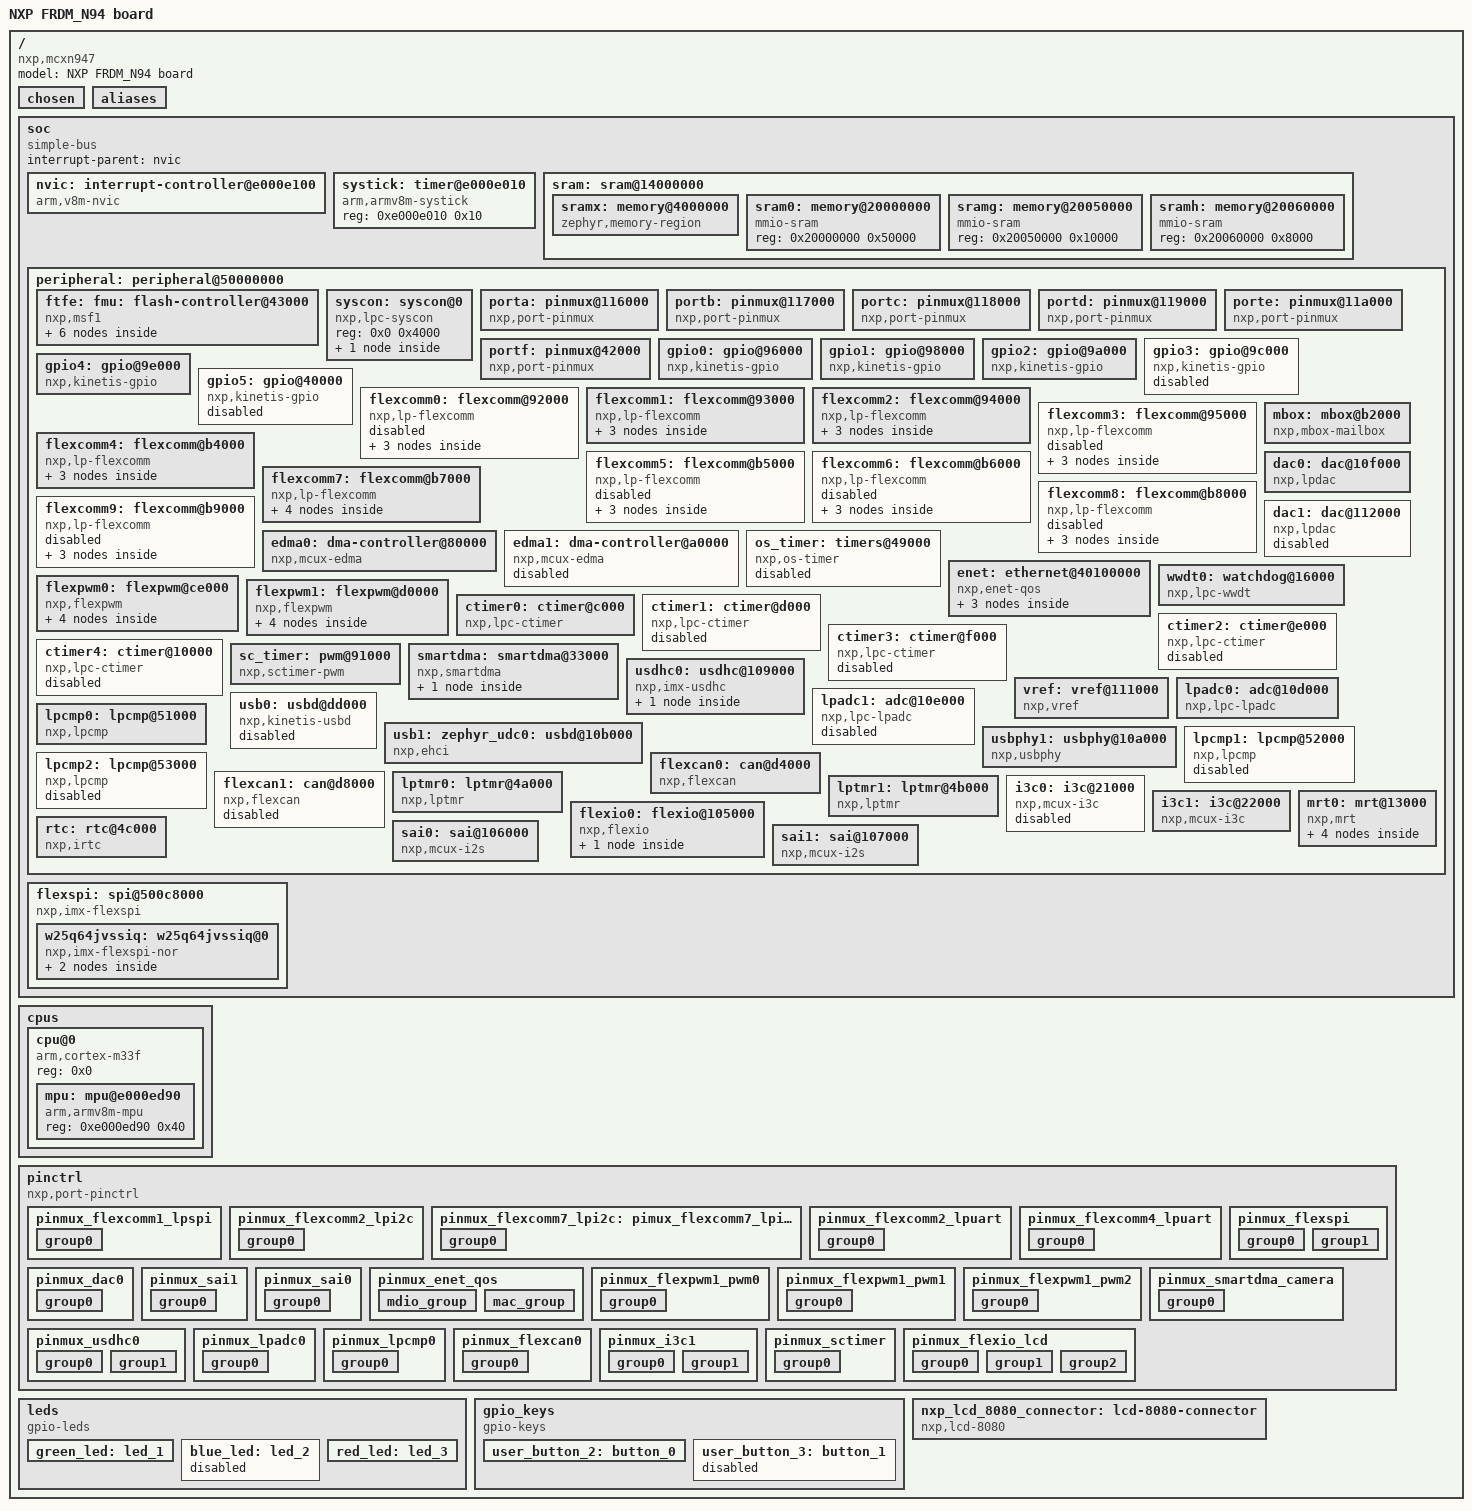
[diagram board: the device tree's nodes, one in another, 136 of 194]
/dts-v1/;

/ {
	#address-cells = < 0x1 >;
	#size-cells = < 0x1 >;
	model = "NXP FRDM_N94 board";
	compatible = "nxp,mcxn947", "nxp,mcx";
	chosen {
		zephyr,sram = &sram0;
		zephyr,flash = &flash;
		zephyr,flash-controller = &fmu;
		zephyr,code-partition = &slot0_partition;
		zephyr,uart-mcumgr = &flexcomm4_lpuart4;
		zephyr,console = &flexcomm4_lpuart4;
		zephyr,shell-uart = &flexcomm4_lpuart4;
		zephyr,canbus = &flexcan0;
		zephyr,code-cpu1-partition = &slot1_partition;
	};
	aliases {
		led0 = &red_led;
		led1 = &green_led;
		led2 = &blue_led;
		sw0 = &user_button_2;
		sw1 = &user_button_3;
		sdhc0 = &usdhc0;
		mcuboot-button0 = &user_button_2;
		watchdog0 = &wwdt0;
		pwm-0 = &flexpwm1_pwm0;
		pwm-1 = &sc_timer;
		rtc = &rtc;
	};
	soc {
		#address-cells = < 0x1 >;
		#size-cells = < 0x1 >;
		compatible = "simple-bus";
		interrupt-parent = < &nvic >;
		ranges;
		nvic: interrupt-controller@e000e100 {
			#address-cells = < 0x1 >;
			compatible = "arm,v8m-nvic";
			reg = < 0xe000e100 0xc00 >;
			interrupt-controller;
			#interrupt-cells = < 0x2 >;
			arm,num-irq-priority-bits = < 0x3 >;
			phandle = < 0x1 >;
		};
		systick: timer@e000e010 {
			compatible = "arm,armv8m-systick";
			reg = < 0xe000e010 0x10 >;
			status = "okay";
		};
		sram: sram@14000000 {
			ranges = < 0x4000000 0x14000000 0x20000000 >;
			#address-cells = < 0x1 >;
			#size-cells = < 0x1 >;
			sramx: memory@4000000 {
				compatible = "zephyr,memory-region", "mmio-sram";
				reg = < 0x4000000 0x18000 >;
				zephyr,memory-region = "SRAM1";
				zephyr,memory-attr = < 0x100000 >;
			};
			sram0: memory@20000000 {
				compatible = "mmio-sram";
				reg = < 0x20000000 0x50000 >;
			};
			sramg: memory@20050000 {
				compatible = "mmio-sram";
				reg = < 0x20050000 0x10000 >;
			};
			sramh: memory@20060000 {
				compatible = "mmio-sram";
				reg = < 0x20060000 0x8000 >;
			};
		};
		peripheral: peripheral@50000000 {
			ranges = < 0x0 0x50000000 0x10000000 >;
			#address-cells = < 0x1 >;
			#size-cells = < 0x1 >;
			ftfe: fmu: flash-controller@43000 {
				ranges = < 0x0 0x10000000 0x4000000 >;
				compatible = "nxp,msf1";
				reg = < 0x43000 0x1000 >;
				interrupts = < 0x8a 0x0 >;
				status = "okay";
				#address-cells = < 0x1 >;
				#size-cells = < 0x1 >;
				flash: flash@0 {
					compatible = "soc-nv-flash";
					reg = < 0x0 0x200000 >;
					erase-block-size = < 0x2000 >;
					write-block-size = < 0x80 >;
					partitions {
						compatible = "fixed-partitions";
						#address-cells = < 0x1 >;
						#size-cells = < 0x1 >;
						boot_partition: partition@0 {
							label = "mcuboot";
							reg = < 0x0 0x14000 >;
						};
						slot0_partition: partition@14000 {
							label = "image-0";
							reg = < 0x14000 0xf6000 >;
						};
						slot1_partition: partition@10A000 {
							label = "image-1";
							reg = < 0x10a000 0xf6000 >;
						};
					};
				};
				uuid: uuid@1100000 {
					compatible = "nxp,lpc-uid";
					reg = < 0x1100000 0x10 >;
				};
			};
			syscon: syscon@0 {
				compatible = "nxp,lpc-syscon";
				reg = < 0x0 0x4000 >;
				#clock-cells = < 0x1 >;
				phandle = < 0x2 >;
				reset: reset {
					compatible = "nxp,lpc-syscon-reset";
					#reset-cells = < 0x1 >;
					phandle = < 0x22 >;
				};
			};
			porta: pinmux@116000 {
				compatible = "nxp,port-pinmux";
				reg = < 0x116000 0x1000 >;
				clocks = < &syscon 0xc00 >;
				phandle = < 0x3 >;
			};
			portb: pinmux@117000 {
				compatible = "nxp,port-pinmux";
				reg = < 0x117000 0x1000 >;
				clocks = < &syscon 0xc01 >;
				phandle = < 0x4 >;
			};
			portc: pinmux@118000 {
				compatible = "nxp,port-pinmux";
				reg = < 0x118000 0x1000 >;
				clocks = < &syscon 0xc02 >;
				phandle = < 0x5 >;
			};
			portd: pinmux@119000 {
				compatible = "nxp,port-pinmux";
				reg = < 0x119000 0x1000 >;
				clocks = < &syscon 0xc03 >;
				phandle = < 0x6 >;
			};
			porte: pinmux@11a000 {
				compatible = "nxp,port-pinmux";
				reg = < 0x11a000 0x1000 >;
				clocks = < &syscon 0xc04 >;
				phandle = < 0x7 >;
			};
			portf: pinmux@42000 {
				compatible = "nxp,port-pinmux";
				reg = < 0x42000 0x1000 >;
				clocks = < &syscon 0xc05 >;
				phandle = < 0x8 >;
			};
			gpio0: gpio@96000 {
				compatible = "nxp,kinetis-gpio";
				status = "okay";
				reg = < 0x96000 0x1000 >;
				interrupts = < 0x11 0x0 >, < 0x12 0x0 >;
				gpio-controller;
				#gpio-cells = < 0x2 >;
				nxp,kinetis-port = < &porta >;
				phandle = < 0x20 >;
			};
			gpio1: gpio@98000 {
				compatible = "nxp,kinetis-gpio";
				status = "okay";
				reg = < 0x98000 0x1000 >;
				interrupts = < 0x13 0x0 >, < 0x14 0x0 >;
				gpio-controller;
				#gpio-cells = < 0x2 >;
				nxp,kinetis-port = < &portb >;
				phandle = < 0xf >;
			};
			gpio2: gpio@9a000 {
				compatible = "nxp,kinetis-gpio";
				status = "okay";
				reg = < 0x9a000 0x1000 >;
				interrupts = < 0x15 0x0 >, < 0x16 0x0 >;
				gpio-controller;
				#gpio-cells = < 0x2 >;
				nxp,kinetis-port = < &portc >;
				phandle = < 0x18 >;
			};
			gpio3: gpio@9c000 {
				compatible = "nxp,kinetis-gpio";
				status = "disabled";
				reg = < 0x9c000 0x1000 >;
				interrupts = < 0x17 0x0 >, < 0x18 0x0 >;
				gpio-controller;
				#gpio-cells = < 0x2 >;
				nxp,kinetis-port = < &portd >;
			};
			gpio4: gpio@9e000 {
				compatible = "nxp,kinetis-gpio";
				status = "okay";
				reg = < 0x9e000 0x1000 >;
				interrupts = < 0x19 0x0 >, < 0x1a 0x0 >;
				gpio-controller;
				#gpio-cells = < 0x2 >;
				nxp,kinetis-port = < &porte >;
				phandle = < 0x1f >;
			};
			gpio5: gpio@40000 {
				compatible = "nxp,kinetis-gpio";
				status = "disabled";
				reg = < 0x40000 0x1000 >;
				interrupts = < 0x1b 0x0 >, < 0x1c 0x0 >;
				gpio-controller;
				#gpio-cells = < 0x2 >;
				nxp,kinetis-port = < &portf >;
			};
			flexcomm0: flexcomm@92000 {
				compatible = "nxp,lp-flexcomm";
				reg = < 0x92000 0x1000 >;
				interrupts = < 0x23 0x0 >;
				status = "disabled";
				ranges;
				#address-cells = < 0x1 >;
				#size-cells = < 0x1 >;
				flexcomm0_lpuart0: lpuart@92000 {
					compatible = "nxp,lpuart";
					reg = < 0x92000 0x1000 >;
					clocks = < &syscon 0x100 >;
					status = "disabled";
				};
				flexcomm0_lpspi0: spi@92000 {
					compatible = "nxp,lpspi";
					reg = < 0x92000 0x1000 >;
					clocks = < &syscon 0x100 >;
					#address-cells = < 0x1 >;
					#size-cells = < 0x0 >;
					tx-fifo-size = < 0x8 >;
					rx-fifo-size = < 0x8 >;
					status = "disabled";
				};
				flexcomm0_lpi2c0: lpi2c@92800 {
					compatible = "nxp,lpi2c";
					reg = < 0x92800 0x1000 >;
					clocks = < &syscon 0x100 >;
					#address-cells = < 0x1 >;
					#size-cells = < 0x0 >;
					status = "disabled";
				};
			};
			flexcomm1: flexcomm@93000 {
				compatible = "nxp,lp-flexcomm";
				reg = < 0x93000 0x1000 >;
				interrupts = < 0x24 0x0 >;
				status = "okay";
				ranges;
				#address-cells = < 0x1 >;
				#size-cells = < 0x1 >;
				flexcomm1_lpuart1: lpuart@93000 {
					compatible = "nxp,lpuart";
					reg = < 0x93000 0x1000 >;
					clocks = < &syscon 0x101 >;
					dmas = < &edma0 0x0 0x47 >, < &edma0 0x1 0x48 >;
					dma-names = "rx", "tx";
					status = "disabled";
				};
				flexcomm1_lpspi1: spi@93000 {
					compatible = "nxp,lpspi";
					reg = < 0x93000 0x1000 >;
					clocks = < &syscon 0x101 >;
					#address-cells = < 0x1 >;
					#size-cells = < 0x0 >;
					dmas = < &edma0 0x0 0x47 >, < &edma0 0x1 0x48 >;
					dma-names = "rx", "tx";
					tx-fifo-size = < 0x8 >;
					rx-fifo-size = < 0x8 >;
					status = "okay";
					pinctrl-0 = < &pinmux_flexcomm1_lpspi >;
					pinctrl-names = "default";
				};
				flexcomm1_lpi2c1: lpi2c@93800 {
					compatible = "nxp,lpi2c";
					reg = < 0x93800 0x1000 >;
					clocks = < &syscon 0x101 >;
					#address-cells = < 0x1 >;
					#size-cells = < 0x0 >;
					status = "disabled";
				};
			};
			flexcomm2: flexcomm@94000 {
				compatible = "nxp,lp-flexcomm";
				reg = < 0x94000 0x1000 >;
				interrupts = < 0x25 0x0 >;
				status = "okay";
				ranges;
				#address-cells = < 0x1 >;
				#size-cells = < 0x1 >;
				flexcomm2_lpuart2: lpuart@94000 {
					compatible = "nxp,lpuart";
					reg = < 0x94000 0x1000 >;
					clocks = < &syscon 0x102 >;
					dmas = < &edma0 0x4 0x49 >, < &edma0 0x5 0x4a >;
					dma-names = "rx", "tx";
					status = "okay";
					current-speed = < 0x1c200 >;
					pinctrl-0 = < &pinmux_flexcomm2_lpuart >;
					pinctrl-names = "default";
				};
				flexcomm2_lpspi2: spi@94000 {
					compatible = "nxp,lpspi";
					reg = < 0x94000 0x1000 >;
					clocks = < &syscon 0x102 >;
					#address-cells = < 0x1 >;
					#size-cells = < 0x0 >;
					dmas = < &edma0 0x4 0x49 >, < &edma0 0x5 0x4a >;
					dma-names = "rx", "tx";
					tx-fifo-size = < 0x8 >;
					rx-fifo-size = < 0x8 >;
					status = "disabled";
				};
				flexcomm2_lpi2c2: nxp_8080_touch_panel_i2c: lpi2c@94800 {
					compatible = "nxp,lpi2c";
					reg = < 0x94800 0x1000 >;
					clocks = < &syscon 0x102 >;
					#address-cells = < 0x1 >;
					#size-cells = < 0x0 >;
					status = "okay";
					pinctrl-0 = < &pinmux_flexcomm2_lpi2c >;
					pinctrl-names = "default";
					clock-frequency = < 0x186a0 >;
				};
			};
			flexcomm3: flexcomm@95000 {
				compatible = "nxp,lp-flexcomm";
				reg = < 0x95000 0x1000 >;
				interrupts = < 0x26 0x0 >;
				status = "disabled";
				ranges;
				#address-cells = < 0x1 >;
				#size-cells = < 0x1 >;
				flexcomm3_lpuart3: lpuart@95000 {
					compatible = "nxp,lpuart";
					reg = < 0x95000 0x1000 >;
					clocks = < &syscon 0x103 >;
					status = "disabled";
				};
				flexcomm3_lpspi3: spi@95000 {
					compatible = "nxp,lpspi";
					reg = < 0x95000 0x1000 >;
					clocks = < &syscon 0x103 >;
					#address-cells = < 0x1 >;
					#size-cells = < 0x0 >;
					tx-fifo-size = < 0x8 >;
					rx-fifo-size = < 0x8 >;
					status = "disabled";
				};
				flexcomm3_lpi2c3: lpi2c@95800 {
					compatible = "nxp,lpi2c";
					reg = < 0x95800 0x1000 >;
					clocks = < &syscon 0x103 >;
					#address-cells = < 0x1 >;
					#size-cells = < 0x0 >;
					status = "disabled";
				};
			};
			flexcomm4: flexcomm@b4000 {
				compatible = "nxp,lp-flexcomm";
				reg = < 0xb4000 0x1000 >;
				interrupts = < 0x27 0x0 >;
				status = "okay";
				ranges;
				#address-cells = < 0x1 >;
				#size-cells = < 0x1 >;
				flexcomm4_lpuart4: lpuart@b4000 {
					compatible = "nxp,lpuart";
					reg = < 0xb4000 0x1000 >;
					clocks = < &syscon 0x104 >;
					dmas = < &edma0 0x2 0x4d >, < &edma0 0x3 0x4e >;
					dma-names = "rx", "tx";
					status = "okay";
					current-speed = < 0x1c200 >;
					pinctrl-0 = < &pinmux_flexcomm4_lpuart >;
					pinctrl-names = "default";
				};
				flexcomm4_lpspi4: spi@b4000 {
					compatible = "nxp,lpspi";
					reg = < 0xb4000 0x1000 >;
					clocks = < &syscon 0x104 >;
					#address-cells = < 0x1 >;
					#size-cells = < 0x0 >;
					dmas = < &edma0 0x2 0x4d >, < &edma0 0x3 0x4e >;
					dma-names = "rx", "tx";
					tx-fifo-size = < 0x8 >;
					rx-fifo-size = < 0x8 >;
					status = "disabled";
				};
				flexcomm4_lpi2c4: lpi2c@b4800 {
					compatible = "nxp,lpi2c";
					reg = < 0xb4800 0x1000 >;
					clocks = < &syscon 0x104 >;
					#address-cells = < 0x1 >;
					#size-cells = < 0x0 >;
					status = "disabled";
				};
			};
			flexcomm5: flexcomm@b5000 {
				compatible = "nxp,lp-flexcomm";
				reg = < 0xb5000 0x1000 >;
				interrupts = < 0x28 0x0 >;
				status = "disabled";
				ranges;
				#address-cells = < 0x1 >;
				#size-cells = < 0x1 >;
				flexcomm5_lpuart5: lpuart@b5000 {
					compatible = "nxp,lpuart";
					reg = < 0xb5000 0x1000 >;
					clocks = < &syscon 0x105 >;
					status = "disabled";
				};
				flexcomm5_lpspi5: spi@b5000 {
					compatible = "nxp,lpspi";
					reg = < 0xb5000 0x1000 >;
					clocks = < &syscon 0x105 >;
					#address-cells = < 0x1 >;
					#size-cells = < 0x0 >;
					tx-fifo-size = < 0x8 >;
					rx-fifo-size = < 0x8 >;
					status = "disabled";
				};
				flexcomm5_lpi2c5: lpi2c@b5800 {
					compatible = "nxp,lpi2c";
					reg = < 0xb5800 0x1000 >;
					clocks = < &syscon 0x105 >;
					#address-cells = < 0x1 >;
					#size-cells = < 0x0 >;
					status = "disabled";
				};
			};
			flexcomm6: flexcomm@b6000 {
				compatible = "nxp,lp-flexcomm";
				reg = < 0xb6000 0x1000 >;
				interrupts = < 0x29 0x0 >;
				status = "disabled";
				ranges;
				#address-cells = < 0x1 >;
				#size-cells = < 0x1 >;
				flexcomm6_lpuart6: lpuart@b6000 {
					compatible = "nxp,lpuart";
					reg = < 0xb6000 0x1000 >;
					clocks = < &syscon 0x106 >;
					status = "disabled";
				};
				flexcomm6_lpspi6: spi@b6000 {
					compatible = "nxp,lpspi";
					reg = < 0xb6000 0x1000 >;
					clocks = < &syscon 0x106 >;
					#address-cells = < 0x1 >;
					#size-cells = < 0x0 >;
					tx-fifo-size = < 0x8 >;
					rx-fifo-size = < 0x8 >;
					status = "disabled";
				};
				flexcomm6_lpi2c6: lpi2c@b6800 {
					compatible = "nxp,lpi2c";
					reg = < 0xb6800 0x1000 >;
					clocks = < &syscon 0x106 >;
					#address-cells = < 0x1 >;
					#size-cells = < 0x0 >;
					status = "disabled";
				};
			};
			flexcomm7: flexcomm@b7000 {
				compatible = "nxp,lp-flexcomm";
				reg = < 0xb7000 0x1000 >;
				interrupts = < 0x2a 0x0 >;
				status = "okay";
				ranges;
				#address-cells = < 0x1 >;
				#size-cells = < 0x1 >;
				flexcomm7_lpuart7: lpuart@b7000 {
					compatible = "nxp,lpuart";
					reg = < 0xb7000 0x1000 >;
					clocks = < &syscon 0x107 >;
					status = "disabled";
				};
				flexcomm7_lpspi7: spi@b7000 {
					compatible = "nxp,lpspi";
					reg = < 0xb7000 0x1000 >;
					clocks = < &syscon 0x107 >;
					#address-cells = < 0x1 >;
					#size-cells = < 0x0 >;
					tx-fifo-size = < 0x8 >;
					rx-fifo-size = < 0x8 >;
					status = "disabled";
				};
				flexcomm7_lpi2c7: lpi2c@b7800 {
					compatible = "nxp,lpi2c";
					reg = < 0xb7800 0x1000 >;
					clocks = < &syscon 0x107 >;
					#address-cells = < 0x1 >;
					#size-cells = < 0x0 >;
					status = "okay";
					pinctrl-0 = < &pinmux_flexcomm7_lpi2c >;
					pinctrl-names = "default";
					clock-frequency = < 0x186a0 >;
					ov7670: ov7670@21 {
						compatible = "ovti,ov7670";
						reset-gpios = < &gpio1 0x13 0x0 >;
						pwdn-gpios = < &gpio1 0x12 0x0 >;
						reg = < 0x21 >;
						phandle = < 0x16 >;
					};
				};
			};
			flexcomm8: flexcomm@b8000 {
				compatible = "nxp,lp-flexcomm";
				reg = < 0xb8000 0x1000 >;
				interrupts = < 0x2b 0x0 >;
				status = "disabled";
				ranges;
				#address-cells = < 0x1 >;
				#size-cells = < 0x1 >;
				flexcomm8_lpuart8: lpuart@b8000 {
					compatible = "nxp,lpuart";
					reg = < 0xb8000 0x1000 >;
					clocks = < &syscon 0x108 >;
					status = "disabled";
				};
				flexcomm8_lpspi8: spi@b8000 {
					compatible = "nxp,lpspi";
					reg = < 0xb8000 0x1000 >;
					clocks = < &syscon 0x108 >;
					#address-cells = < 0x1 >;
					#size-cells = < 0x0 >;
					tx-fifo-size = < 0x8 >;
					rx-fifo-size = < 0x8 >;
					status = "disabled";
				};
				flexcomm8_lpi2c8: lpi2c@b8800 {
					compatible = "nxp,lpi2c";
					reg = < 0xb8800 0x1000 >;
					clocks = < &syscon 0x108 >;
					#address-cells = < 0x1 >;
					#size-cells = < 0x0 >;
					status = "disabled";
				};
			};
			flexcomm9: flexcomm@b9000 {
				compatible = "nxp,lp-flexcomm";
				reg = < 0xb9000 0x1000 >;
				interrupts = < 0x2c 0x0 >;
				status = "disabled";
				ranges;
				#address-cells = < 0x1 >;
				#size-cells = < 0x1 >;
				flexcomm9_lpuart9: lpuart@b9000 {
					compatible = "nxp,lpuart";
					reg = < 0xb9000 0x1000 >;
					clocks = < &syscon 0x109 >;
					status = "disabled";
				};
				flexcomm9_lpspi9: spi@b9000 {
					compatible = "nxp,lpspi";
					reg = < 0xb9000 0x1000 >;
					clocks = < &syscon 0x109 >;
					#address-cells = < 0x1 >;
					#size-cells = < 0x0 >;
					tx-fifo-size = < 0x8 >;
					rx-fifo-size = < 0x8 >;
					status = "disabled";
				};
				flexcomm9_lpi2c9: lpi2c@b9800 {
					compatible = "nxp,lpi2c";
					reg = < 0xb9800 0x1000 >;
					clocks = < &syscon 0x109 >;
					#address-cells = < 0x1 >;
					#size-cells = < 0x0 >;
					status = "disabled";
				};
			};
			mbox: mbox@b2000 {
				compatible = "nxp,mbox-mailbox";
				reg = < 0xb2000 0xec >;
				interrupts = < 0x36 0x0 >;
				rx-channels = < 0x4 >;
				#mbox-cells = < 0x1 >;
				status = "okay";
			};
			edma0: dma-controller@80000 {
				#dma-cells = < 0x2 >;
				compatible = "nxp,mcux-edma";
				nxp,version = < 0x4 >;
				dma-channels = < 0x10 >;
				dma-requests = < 0x78 >;
				reg = < 0x80000 0x1000 >;
				interrupts = < 0x1 0x0 >, < 0x2 0x0 >, < 0x3 0x0 >, < 0x4 0x0 >, < 0x5 0x0 >, < 0x6 0x0 >, < 0x7 0x0 >, < 0x8 0x0 >, < 0x9 0x0 >, < 0xa 0x0 >, < 0xb 0x0 >, < 0xc 0x0 >, < 0xd 0x0 >, < 0xe 0x0 >, < 0xf 0x0 >, < 0x10 0x0 >;
				no-error-irq;
				status = "okay";
				phandle = < 0x9 >;
			};
			edma1: dma-controller@a0000 {
				#dma-cells = < 0x2 >;
				compatible = "nxp,mcux-edma";
				nxp,version = < 0x4 >;
				dma-channels = < 0x10 >;
				dma-requests = < 0x78 >;
				reg = < 0xa0000 0x1000 >;
				interrupts = < 0x4d 0x0 >, < 0x4e 0x0 >, < 0x4f 0x0 >, < 0x50 0x0 >, < 0x51 0x0 >, < 0x52 0x0 >, < 0x53 0x0 >, < 0x54 0x0 >, < 0x55 0x0 >, < 0x56 0x0 >, < 0x57 0x0 >, < 0x58 0x0 >, < 0x59 0x0 >, < 0x5a 0x0 >, < 0x5b 0x0 >, < 0x5c 0x0 >;
				no-error-irq;
				status = "disabled";
			};
			os_timer: timers@49000 {
				compatible = "nxp,os-timer";
				reg = < 0x49000 0x1000 >;
				interrupts = < 0x39 0x0 >;
				status = "disabled";
			};
			dac0: dac@10f000 {
				compatible = "nxp,lpdac";
				reg = < 0x10f000 0x1000 >;
				interrupts = < 0x6a 0x0 >;
				status = "okay";
				voltage-reference = < 0x0 >;
				#io-channel-cells = < 0x1 >;
				pinctrl-0 = < &pinmux_dac0 >;
				pinctrl-names = "default";
			};
			dac1: dac@112000 {
				compatible = "nxp,lpdac";
				reg = < 0x112000 0x1000 >;
				interrupts = < 0x6b 0x0 >;
				status = "disabled";
				voltage-reference = < 0x0 >;
				#io-channel-cells = < 0x1 >;
			};
			enet: ethernet@40100000 {
				compatible = "nxp,enet-qos";
				reg = < 0x40100000 0x1200 >;
				clocks = < &syscon 0xd00 >;
				pinctrl-0 = < &pinmux_enet_qos >;
				pinctrl-names = "default";
				status = "okay";
				enet_mac: ethernet {
					compatible = "nxp,enet-qos-mac";
					status = "okay";
					interrupts = < 0x8b 0x0 >, < 0x8c 0x0 >, < 0x8d 0x0 >;
					interrupt-names = "mac", "power", "lpi";
					phy-connection-type = "rmii";
					zephyr,random-mac-address;
					phy-handle = < &phy >;
				};
				enet_mdio: mdio {
					#address-cells = < 0x1 >;
					#size-cells = < 0x0 >;
					compatible = "nxp,enet-qos-mdio";
					status = "okay";
					phy: ethernet-phy@0 {
						compatible = "ethernet-phy";
						reg = < 0x0 >;
						status = "okay";
						phandle = < 0x12 >;
					};
				};
			};
			wwdt0: watchdog@16000 {
				compatible = "nxp,lpc-wwdt";
				reg = < 0x16000 0x1000 >;
				interrupts = < 0x98 0x0 >;
				status = "okay";
				clk-divider = < 0x1 >;
			};
			flexpwm0: flexpwm@ce000 {
				compatible = "nxp,flexpwm";
				reg = < 0xce000 0x1000 >;
				interrupt-names = "RELOAD-ERROR", "FAULT";
				interrupts = < 0x70 0x0 >, < 0x71 0x0 >;
				flexpwm0_pwm0: pwm0 {
					compatible = "nxp,imx-pwm";
					index = < 0x0 >;
					interrupts = < 0x72 0x0 >;
					#pwm-cells = < 0x3 >;
					clocks = < &syscon 0x400 >;
					nxp,prescaler = < 0x80 >;
					status = "disabled";
					run-in-wait;
				};
				flexpwm0_pwm1: pwm1 {
					compatible = "nxp,imx-pwm";
					index = < 0x1 >;
					interrupts = < 0x73 0x0 >;
					#pwm-cells = < 0x3 >;
					clocks = < &syscon 0x400 >;
					nxp,prescaler = < 0x80 >;
					status = "disabled";
					run-in-wait;
				};
				flexpwm0_pwm2: pwm2 {
					compatible = "nxp,imx-pwm";
					index = < 0x2 >;
					interrupts = < 0x74 0x0 >;
					#pwm-cells = < 0x3 >;
					clocks = < &syscon 0x400 >;
					nxp,prescaler = < 0x80 >;
					status = "disabled";
					run-in-wait;
				};
				flexpwm0_pwm3: pwm3 {
					compatible = "nxp,imx-pwm";
					index = < 0x3 >;
					interrupts = < 0x75 0x0 >;
					#pwm-cells = < 0x3 >;
					clocks = < &syscon 0x400 >;
					nxp,prescaler = < 0x80 >;
					status = "disabled";
					run-in-wait;
				};
			};
			flexpwm1: flexpwm@d0000 {
				compatible = "nxp,flexpwm";
				reg = < 0xd0000 0x1000 >;
				interrupt-names = "RELOAD-ERROR", "FAULT";
				interrupts = < 0x76 0x0 >, < 0x77 0x0 >;
				flexpwm1_pwm0: pwm0 {
					compatible = "nxp,imx-pwm";
					index = < 0x0 >;
					interrupts = < 0x78 0x0 >;
					#pwm-cells = < 0x3 >;
					clocks = < &syscon 0x400 >;
					nxp,prescaler = < 0x80 >;
					status = "okay";
					run-in-wait;
					pinctrl-0 = < &pinmux_flexpwm1_pwm0 >;
					pinctrl-names = "default";
				};
				flexpwm1_pwm1: pwm1 {
					compatible = "nxp,imx-pwm";
					index = < 0x1 >;
					interrupts = < 0x79 0x0 >;
					#pwm-cells = < 0x3 >;
					clocks = < &syscon 0x400 >;
					nxp,prescaler = < 0x80 >;
					status = "disabled";
					run-in-wait;
				};
				flexpwm1_pwm2: pwm2 {
					compatible = "nxp,imx-pwm";
					index = < 0x2 >;
					interrupts = < 0x7a 0x0 >;
					#pwm-cells = < 0x3 >;
					clocks = < &syscon 0x400 >;
					nxp,prescaler = < 0x80 >;
					status = "disabled";
					run-in-wait;
				};
				flexpwm1_pwm3: pwm3 {
					compatible = "nxp,imx-pwm";
					index = < 0x3 >;
					interrupts = < 0x7b 0x0 >;
					#pwm-cells = < 0x3 >;
					clocks = < &syscon 0x400 >;
					nxp,prescaler = < 0x80 >;
					status = "disabled";
					run-in-wait;
				};
			};
			ctimer0: ctimer@c000 {
				compatible = "nxp,lpc-ctimer";
				reg = < 0xc000 0x1000 >;
				interrupts = < 0x1f 0x0 >;
				status = "okay";
				clk-source = < 0x1 >;
				clocks = < &syscon 0x0 >;
				mode = < 0x0 >;
				input = < 0x0 >;
				prescale = < 0x0 >;
			};
			ctimer1: ctimer@d000 {
				compatible = "nxp,lpc-ctimer";
				reg = < 0xd000 0x1000 >;
				interrupts = < 0x20 0x0 >;
				status = "disabled";
				clk-source = < 0x1 >;
				clocks = < &syscon 0x1 >;
				mode = < 0x0 >;
				input = < 0x0 >;
				prescale = < 0x0 >;
			};
			ctimer2: ctimer@e000 {
				compatible = "nxp,lpc-ctimer";
				reg = < 0xe000 0x1000 >;
				interrupts = < 0x22 0x0 >;
				status = "disabled";
				clk-source = < 0x1 >;
				clocks = < &syscon 0x2 >;
				mode = < 0x0 >;
				input = < 0x0 >;
				prescale = < 0x0 >;
			};
			ctimer3: ctimer@f000 {
				compatible = "nxp,lpc-ctimer";
				reg = < 0xf000 0x1000 >;
				interrupts = < 0x37 0x0 >;
				status = "disabled";
				clk-source = < 0x1 >;
				clocks = < &syscon 0x3 >;
				mode = < 0x0 >;
				input = < 0x0 >;
				prescale = < 0x0 >;
			};
			ctimer4: ctimer@10000 {
				compatible = "nxp,lpc-ctimer";
				reg = < 0x10000 0x1000 >;
				interrupts = < 0x38 0x0 >;
				status = "disabled";
				clk-source = < 0x1 >;
				clocks = < &syscon 0x4 >;
				mode = < 0x0 >;
				input = < 0x0 >;
				prescale = < 0x0 >;
			};
			sc_timer: pwm@91000 {
				compatible = "nxp,sctimer-pwm";
				reg = < 0x91000 0x1000 >;
				interrupts = < 0x21 0x0 >;
				clocks = < &syscon 0x900 >;
				status = "okay";
				prescaler = < 0x1 >;
				#pwm-cells = < 0x3 >;
				pinctrl-0 = < &pinmux_sctimer >;
				pinctrl-names = "default";
			};
			smartdma: smartdma@33000 {
				compatible = "nxp,smartdma";
				reg = < 0x33000 0x1000 >;
				status = "okay";
				interrupts = < 0x35 0x0 >;
				program-mem = < 0x4000000 >;
				#dma-cells = < 0x0 >;
				video_sdma: video-sdma {
					status = "okay";
					compatible = "nxp,video-smartdma";
					pinctrl-0 = < &pinmux_smartdma_camera >;
					pinctrl-names = "default";
					sensor = < &ov7670 >;
					vsync-pin = < 0x4 >;
					hsync-pin = < 0xb >;
					pclk-pin = < 0x5 >;
				};
			};
			usdhc0: usdhc@109000 {
				compatible = "nxp,imx-usdhc";
				reg = < 0x109000 0x1000 >;
				interrupts = < 0x3d 0x0 >;
				status = "okay";
				clocks = < &syscon 0x200 >;
				max-bus-freq = < 0x3197500 >;
				min-bus-freq = < 0x61a80 >;
				pinctrl-0 = < &pinmux_usdhc0 >;
				pinctrl-1 = < &pinmux_usdhc0 >;
				pinctrl-2 = < &pinmux_usdhc0 >;
				cd-gpios = < &gpio2 0x1 0x1 >;
				pinctrl-names = "default", "slow", "med";
				no-1-8-v;
				sdmmc {
					compatible = "zephyr,sdmmc-disk";
					disk-name = "SD";
					status = "okay";
				};
			};
			vref: vref@111000 {
				compatible = "nxp,vref";
				regulator-name = "mcxn94x-vref";
				reg = < 0x111000 0x14 >;
				status = "okay";
				#nxp,reference-cells = < 0x1 >;
				nxp,buffer-startup-delay-us = < 0x190 >;
				nxp,bandgap-startup-time-us = < 0x14 >;
				regulator-min-microvolt = < 0xf4240 >;
				regulator-max-microvolt = < 0x200b20 >;
				phandle = < 0x19 >;
			};
			lpadc0: adc@10d000 {
				compatible = "nxp,lpc-lpadc";
				reg = < 0x10d000 0x1000 >;
				interrupts = < 0x2d 0x0 >;
				status = "okay";
				voltage-ref = < 0x1 >;
				calibration-average = < 0x80 >;
				power-level = < 0x0 >;
				offset-value-a = < 0x0 >;
				offset-value-b = < 0x0 >;
				#io-channel-cells = < 0x1 >;
				clocks = < &syscon 0xf00 >;
				nxp,references = < &vref 0x708 >;
				pinctrl-0 = < &pinmux_lpadc0 >;
				pinctrl-names = "default";
			};
			lpadc1: adc@10e000 {
				compatible = "nxp,lpc-lpadc";
				reg = < 0x10e000 0x1000 >;
				interrupts = < 0x2e 0x0 >;
				status = "disabled";
				voltage-ref = < 0x0 >;
				calibration-average = < 0x80 >;
				power-level = < 0x1 >;
				offset-value-a = < 0x0 >;
				offset-value-b = < 0x0 >;
				#io-channel-cells = < 0x1 >;
				clocks = < &syscon 0xf01 >;
			};
			usb0: usbd@dd000 {
				compatible = "nxp,kinetis-usbd";
				reg = < 0xdd000 0x1000 >;
				interrupts = < 0x32 0x1 >;
				interrupt-names = "usbfs0";
				num-bidir-endpoints = < 0x10 >;
				no-voltage-regulator;
				status = "disabled";
			};
			usb1: zephyr_udc0: usbd@10b000 {
				compatible = "nxp,ehci";
				reg = < 0x10b000 0x1000 >;
				interrupts = < 0x43 0x0 >;
				interrupt-names = "usb_otg";
				num-bidir-endpoints = < 0x8 >;
				status = "okay";
				phy-handle = < &usbphy1 >;
			};
			usbphy1: usbphy@10a000 {
				compatible = "nxp,usbphy";
				reg = < 0x10a000 0x1000 >;
				status = "okay";
				tx-d-cal = < 0x4 >;
				tx-cal-45-dp-ohms = < 0x7 >;
				tx-cal-45-dm-ohms = < 0x7 >;
				phandle = < 0x1b >;
			};
			lpcmp0: lpcmp@51000 {
				compatible = "nxp,lpcmp";
				reg = < 0x51000 0x1000 >;
				interrupts = < 0x6d 0x0 >;
				status = "okay";
				#io-channel-cells = < 0x2 >;
				pinctrl-0 = < &pinmux_lpcmp0 >;
				pinctrl-names = "default";
			};
			lpcmp1: lpcmp@52000 {
				compatible = "nxp,lpcmp";
				reg = < 0x52000 0x1000 >;
				interrupts = < 0x6e 0x0 >;
				status = "disabled";
				#io-channel-cells = < 0x2 >;
			};
			lpcmp2: lpcmp@53000 {
				compatible = "nxp,lpcmp";
				reg = < 0x53000 0x1000 >;
				interrupts = < 0x6f 0x0 >;
				status = "disabled";
				#io-channel-cells = < 0x2 >;
			};
			flexcan0: can@d4000 {
				compatible = "nxp,flexcan";
				reg = < 0xd4000 0x4000 >;
				interrupts = < 0x3e 0x0 >;
				interrupt-names = "common";
				clocks = < &syscon 0x1000 >;
				clk-source = < 0x0 >;
				status = "okay";
				pinctrl-0 = < &pinmux_flexcan0 >;
				pinctrl-names = "default";
			};
			flexcan1: can@d8000 {
				compatible = "nxp,flexcan";
				reg = < 0xd8000 0x4000 >;
				interrupts = < 0x3f 0x0 >;
				interrupt-names = "common";
				clocks = < &syscon 0x1001 >;
				clk-source = < 0x0 >;
				status = "disabled";
			};
			lptmr0: lptmr@4a000 {
				compatible = "nxp,lptmr";
				reg = < 0x4a000 0x1000 >;
				interrupts = < 0x8f 0x0 >;
				clock-frequency = < 0x3e80 >;
				prescaler = < 0x1 >;
				clk-source = < 0x1 >;
				resolution = < 0x20 >;
				status = "okay";
			};
			lptmr1: lptmr@4b000 {
				compatible = "nxp,lptmr";
				reg = < 0x4b000 0x1000 >;
				interrupts = < 0x90 0x0 >;
				clock-frequency = < 0x3e80 >;
				prescaler = < 0x1 >;
				clk-source = < 0x1 >;
				resolution = < 0x20 >;
			};
			i3c0: i3c@21000 {
				compatible = "nxp,mcux-i3c";
				reg = < 0x21000 0x1000 >;
				interrupts = < 0x5f 0x0 >;
				clocks = < &syscon 0x600 >;
				clk-divider = < 0x6 >;
				clk-divider-slow = < 0x1 >;
				clk-divider-tc = < 0x1 >;
				status = "disabled";
				#address-cells = < 0x3 >;
				#size-cells = < 0x0 >;
			};
			i3c1: i3c@22000 {
				compatible = "nxp,mcux-i3c";
				reg = < 0x22000 0x1000 >;
				interrupts = < 0x60 0x0 >;
				clocks = < &syscon 0x601 >;
				clk-divider = < 0x6 >;
				clk-divider-slow = < 0x1 >;
				clk-divider-tc = < 0x1 >;
				status = "okay";
				#address-cells = < 0x3 >;
				#size-cells = < 0x0 >;
				pinctrl-0 = < &pinmux_i3c1 >;
				pinctrl-names = "default";
			};
			flexio0: flexio@105000 {
				compatible = "nxp,flexio";
				reg = < 0x105000 0x1000 >;
				status = "okay";
				interrupts = < 0x69 0x0 >;
				clocks = < &syscon 0x1100 >;
				flexio0_lcd: zephyr_mipi_dbi_parallel: flexio0-lcd {
					compatible = "nxp,mipi-dbi-flexio-lcdif";
					status = "disabled";
					dmas = < &edma0 0x0 0x3d >;
					dma-names = "tx";
					shifters-count = < 0x8 >;
					timers-count = < 0x1 >;
					enwr-pin = < 0x1 >;
					rd-pin = < 0x0 >;
					data-pin-start = < 0x10 >;
					reset-gpios = < &gpio4 0x7 0x0 >;
					cs-gpios = < &gpio0 0xc 0x0 >;
					rs-gpios = < &gpio0 0x7 0x0 >;
					pinctrl-0 = < &pinmux_flexio_lcd >;
					pinctrl-names = "default";
				};
			};
			mrt0: mrt@13000 {
				compatible = "nxp,mrt";
				reg = < 0x13000 0x1000 >;
				interrupts = < 0x1e 0x0 >;
				num-channels = < 0x4 >;
				num-bits = < 0x18 >;
				clocks = < &syscon 0xb00 >;
				resets = < &reset 0x10000 >;
				#address-cells = < 0x1 >;
				#size-cells = < 0x0 >;
				mrt0_channel0: mrt0_channel@0 {
					compatible = "nxp,mrt-channel";
					reg = < 0x0 >;
					status = "okay";
				};
				mrt0_channel1: mrt0_channel@1 {
					compatible = "nxp,mrt-channel";
					reg = < 0x1 >;
					status = "disabled";
				};
				mrt0_channel2: mrt0_channel@2 {
					compatible = "nxp,mrt-channel";
					reg = < 0x2 >;
					status = "disabled";
				};
				mrt0_channel3: mrt0_channel@3 {
					compatible = "nxp,mrt-channel";
					reg = < 0x3 >;
					status = "disabled";
				};
			};
			rtc: rtc@4c000 {
				compatible = "nxp,irtc";
				reg = < 0x4c000 0x1000 >;
				status = "okay";
				interrupts = < 0x34 0x0 >;
				prescaler = < 0x1 >;
				clock-frequency = < 0x4000 >;
				clock-src = < 0x0 >;
				alarms-count = < 0x1 >;
			};
			sai0: sai@106000 {
				compatible = "nxp,mcux-i2s";
				#address-cells = < 0x1 >;
				#size-cells = < 0x0 >;
				#pinmux-cells = < 0x2 >;
				reg = < 0x106000 0x1000 >;
				clocks = < &syscon 0x1600 >;
				pinmuxes = < &sai0 0x100 0x40000000 >;
				interrupts = < 0x3b 0x0 >;
				dmas = < &edma0 0x0 0x63 >, < &edma0 0x0 0x64 >;
				dma-names = "rx", "tx";
				nxp,tx-channel = < 0x1 >;
				nxp,tx-dma-channel = < 0x0 >;
				nxp,rx-dma-channel = < 0x1 >;
				status = "okay";
				pinctrl-0 = < &pinmux_sai0 >;
				pinctrl-names = "default";
				phandle = < 0x23 >;
			};
			sai1: sai@107000 {
				compatible = "nxp,mcux-i2s";
				#address-cells = < 0x1 >;
				#size-cells = < 0x0 >;
				#pinmux-cells = < 0x2 >;
				reg = < 0x107000 0x1000 >;
				clocks = < &syscon 0x1601 >;
				pinmuxes = < &sai1 0x100 0x40000000 >;
				interrupts = < 0x3c 0x0 >;
				dmas = < &edma0 0x0 0x65 >, < &edma0 0x0 0x66 >;
				dma-names = "rx", "tx";
				nxp,tx-channel = < 0x1 >;
				nxp,tx-dma-channel = < 0x2 >;
				nxp,rx-dma-channel = < 0x3 >;
				status = "okay";
				pinctrl-0 = < &pinmux_sai1 >;
				pinctrl-names = "default";
				phandle = < 0x25 >;
			};
		};
		flexspi: spi@500c8000 {
			reg = < 0x500c8000 0x1000 >, < 0x90000000 0x800000 >;
			compatible = "nxp,imx-flexspi";
			interrupts = < 0x3a 0x0 >;
			#address-cells = < 0x1 >;
			#size-cells = < 0x0 >;
			status = "okay";
			clocks = < &syscon 0xa00 >;
			pinctrl-0 = < &pinmux_flexspi >;
			pinctrl-names = "default";
			ahb-prefetch;
			ahb-bufferable;
			ahb-cacheable;
			ahb-read-addr-opt;
			combination-mode;
			rx-clock-source = < 0x1 >;
			w25q64jvssiq: w25q64jvssiq@0 {
				compatible = "nxp,imx-flexspi-nor";
				status = "okay";
				size = < 0x4000000 >;
				reg = < 0x0 >;
				spi-max-frequency = < 0x7ed6b40 >;
				jedec-id = [ EF 40 17 ];
				erase-block-size = < 0x1000 >;
				write-block-size = < 0x1 >;
				cs-interval-unit = < 0x1 >;
				cs-interval = < 0x2 >;
				cs-hold-time = < 0x3 >;
				cs-setup-time = < 0x3 >;
				data-valid-time = < 0x2 >;
				column-space = < 0x0 >;
				partitions {
					compatible = "fixed-partitions";
					#address-cells = < 0x1 >;
					#size-cells = < 0x1 >;
					storage_partition: partition@0 {
						label = "storage";
						reg = < 0x0 0x800000 >;
					};
				};
			};
		};
	};
	cpus: cpus {
		#address-cells = < 0x1 >;
		#size-cells = < 0x0 >;
		cpu@0 {
			compatible = "arm,cortex-m33f";
			reg = < 0x0 >;
			#address-cells = < 0x1 >;
			#size-cells = < 0x1 >;
			mpu: mpu@e000ed90 {
				compatible = "arm,armv8m-mpu";
				reg = < 0xe000ed90 0x40 >;
			};
		};
	};
	pinctrl: pinctrl {
		compatible = "nxp,port-pinctrl";
		status = "okay";
		pinmux_flexcomm1_lpspi: pinmux_flexcomm1_lpspi {
			phandle = < 0xa >;
			group0 {
				pinmux = < 0x6000200 >, < 0x6400200 >, < 0x6800200 >, < 0x6c00200 >;
				slew-rate = "fast";
				drive-strength = "low";
				input-enable;
			};
		};
		pinmux_flexcomm2_lpi2c: pinmux_flexcomm2_lpi2c {
			phandle = < 0xc >;
			group0 {
				pinmux = < 0x40000200 >, < 0x40400200 >;
				slew-rate = "fast";
				drive-strength = "low";
				input-enable;
				bias-pull-up;
				drive-open-drain;
			};
		};
		pinmux_flexcomm7_lpi2c: pimux_flexcomm7_lpi2c {
			phandle = < 0xe >;
			group0 {
				pinmux = < 0x30800200 >, < 0x30c00200 >;
				slew-rate = "fast";
				drive-strength = "low";
				input-enable;
				bias-pull-up;
				drive-open-drain;
			};
		};
		pinmux_flexcomm2_lpuart: pinmux_flexcomm2_lpuart {
			phandle = < 0xb >;
			group0 {
				pinmux = < 0x40800200 >, < 0x40c00200 >;
				slew-rate = "fast";
				drive-strength = "low";
				input-enable;
			};
		};
		pinmux_flexcomm4_lpuart: pinmux_flexcomm4_lpuart {
			phandle = < 0xd >;
			group0 {
				pinmux = < 0x12000200 >, < 0x12400200 >;
				slew-rate = "fast";
				drive-strength = "low";
				input-enable;
			};
		};
		pinmux_flexspi: pinmux_flexspi {
			phandle = < 0x27 >;
			group0 {
				pinmux = < 0x30000800 >, < 0x31c00800 >, < 0x31800800 >, < 0x32000800 >, < 0x32400800 >;
				input-enable;
				slew-rate = "fast";
				drive-strength = "low";
			};
			group1 {
				pinmux = < 0x32800800 >, < 0x32c00800 >;
				input-enable;
				slew-rate = "fast";
				drive-strength = "low";
				bias-pull-up;
			};
		};
		pinmux_dac0: pinmux_dac0 {
			phandle = < 0x10 >;
			group0 {
				pinmux = < 0x40800000 >;
				drive-strength = "low";
				slew-rate = "fast";
			};
		};
		pinmux_sai1: pinmux_sai1 {
			phandle = < 0x26 >;
			group0 {
				pinmux = < 0x34000a00 >, < 0x34400a00 >, < 0x35000a00 >, < 0x34c00a00 >, < 0x34800a00 >, < 0x35400a00 >;
				drive-strength = "high";
				slew-rate = "fast";
				input-enable;
			};
		};
		pinmux_sai0: pinmux_sai0 {
			phandle = < 0x24 >;
			group0 {
				pinmux = < 0x20800a00 >, < 0x21800a00 >, < 0x21c00a00 >;
				drive-strength = "high";
				slew-rate = "fast";
				input-enable;
			};
		};
		pinmux_enet_qos: pinmux_enet_qos {
			phandle = < 0x11 >;
			mdio_group {
				pinmux = < 0x15000900 >, < 0x15400900 >;
				slew-rate = "fast";
				drive-strength = "low";
				input-enable;
			};
			mac_group {
				pinmux = < 0x13400900 >, < 0x13800900 >, < 0x13c00900 >, < 0x11000900 >, < 0x11400900 >, < 0x11800900 >, < 0x11c00900 >;
				slew-rate = "fast";
				drive-strength = "low";
				input-enable;
			};
		};
		pinmux_flexpwm1_pwm0: pinmux_flexpwm1_pwm0 {
			phandle = < 0x13 >;
			group0 {
				pinmux = < 0x21800500 >, < 0x21c00500 >;
				slew-rate = "fast";
				drive-strength = "low";
			};
		};
		pinmux_flexpwm1_pwm1: pinmux_flexpwm1_pwm1 {
			group0 {
				pinmux = < 0x21000500 >, < 0x21400500 >;
				slew-rate = "fast";
				drive-strength = "low";
			};
		};
		pinmux_flexpwm1_pwm2: pinmux_flexpwm1_pwm2 {
			group0 {
				pinmux = < 0x20800500 >, < 0x20c00500 >;
				slew-rate = "fast";
				drive-strength = "low";
			};
		};
		pinmux_smartdma_camera: pinmux_smartdma_camera {
			phandle = < 0x15 >;
			group0 {
				pinmux = < 0x11000700 >, < 0x11400700 >, < 0x11800700 >, < 0x11c00700 >, < 0x31000700 >, < 0x31400700 >, < 0x12800700 >, < 0x12c00700 >, < 0x1000000 >, < 0x1400000 >, < 0x2c00000 >, < 0x20800100 >, < 0x1800c00 >;
				drive-strength = "low";
				slew-rate = "fast";
				input-enable;
			};
		};
		pinmux_usdhc0: pinmux_usdhc0 {
			phandle = < 0x17 >;
			group0 {
				pinmux = < 0x21400300 >, < 0x20c00300 >, < 0x20800300 >, < 0x21c00300 >, < 0x21800300 >;
				slew-rate = "fast";
				drive-strength = "low";
				bias-pull-up;
				input-enable;
			};
			group1 {
				pinmux = < 0x21000300 >;
				slew-rate = "fast";
				drive-strength = "low";
				input-enable;
			};
		};
		pinmux_lpadc0: pinmux_lpadc0 {
			phandle = < 0x1a >;
			group0 {
				pinmux = < 0x45c00000 >, < 0x43c00000 >, < 0x44c00000 >;
				slew-rate = "fast";
				drive-strength = "low";
			};
		};
		pinmux_lpcmp0: pinmux_lpcmp0 {
			phandle = < 0x1c >;
			group0 {
				pinmux = < 0x10000000 >;
				drive-strength = "low";
				slew-rate = "fast";
				bias-pull-up;
			};
		};
		pinmux_flexcan0: pinmux_flexcan0 {
			phandle = < 0x1d >;
			group0 {
				pinmux = < 0x12800b00 >, < 0x12c00b00 >;
				slew-rate = "fast";
				drive-strength = "low";
				input-enable;
			};
		};
		pinmux_i3c1: pinmux_i3c1 {
			phandle = < 0x1e >;
			group0 {
				pinmux = < 0x14000a00 >, < 0x14400a00 >;
				slew-rate = "fast";
				drive-strength = "low";
				input-enable;
				bias-pull-up;
			};
			group1 {
				pinmux = < 0x12c00a00 >;
				slew-rate = "fast";
				drive-strength = "low";
				input-enable;
			};
		};
		pinmux_sctimer: pinmux_sctimer {
			phandle = < 0x14 >;
			group0 {
				pinmux = < 0x20800400 >;
				slew-rate = "fast";
				drive-strength = "low";
				input-enable;
			};
		};
		pinmux_flexio_lcd: pinmux_flexio_lcd {
			phandle = < 0x21 >;
			group0 {
				pinmux = < 0x22000600 >, < 0x22400600 >, < 0x22800600 >, < 0x22c00600 >, < 0x43000600 >, < 0x43400600 >, < 0x43800600 >, < 0x43c00600 >, < 0x44000600 >, < 0x44400600 >, < 0x44800600 >, < 0x44c00600 >, < 0x45000600 >, < 0x45400600 >, < 0x45800600 >, < 0x45c00600 >, < 0x1c00000 >, < 0x3000000 >, < 0x41c00000 >;
				slew-rate = "fast";
				drive-strength = "low";
				input-enable;
			};
			group1 {
				pinmux = < 0x2000600 >;
				slew-rate = "fast";
				drive-strength = "low";
				input-enable;
				bias-pull-up;
			};
			group2 {
				pinmux = < 0x2400600 >;
				slew-rate = "slow";
				drive-strength = "low";
				input-enable;
				bias-pull-up;
			};
		};
	};
	leds {
		compatible = "gpio-leds";
		green_led: led_1 {
			gpios = < &gpio0 0x1b 0x1 >;
			label = "Green LED";
			status = "okay";
		};
		blue_led: led_2 {
			gpios = < &gpio1 0x2 0x1 >;
			label = "Blue LED";
			status = "disabled";
		};
		red_led: led_3 {
			gpios = < &gpio0 0xa 0x1 >;
			label = "Red LED";
			status = "okay";
		};
	};
	gpio_keys {
		compatible = "gpio-keys";
		user_button_2: button_0 {
			label = "User SW2";
			gpios = < &gpio0 0x17 0x11 >;
			zephyr,code = < 0xb >;
			status = "okay";
		};
		user_button_3: button_1 {
			label = "User SW3";
			gpios = < &gpio0 0x6 0x11 >;
			zephyr,code = < 0x2 >;
			status = "disabled";
		};
	};
	nxp_lcd_8080_connector: lcd-8080-connector {
		compatible = "nxp,lcd-8080";
		#gpio-cells = < 0x2 >;
		gpio-map-mask = < 0xffffffff 0xffffffc0 >;
		gpio-map-pass-thru = < 0x0 0x3f >;
		gpio-map = < 0x9 0x0 &gpio4 0x6 0x0 >, < 0xa 0x0 &gpio4 0x5 0x0 >, < 0xb 0x0 &gpio4 0x7 0x0 >;
	};
};
